AUTOSAR XML (schema 4-0-3)
package /ComponentTypes
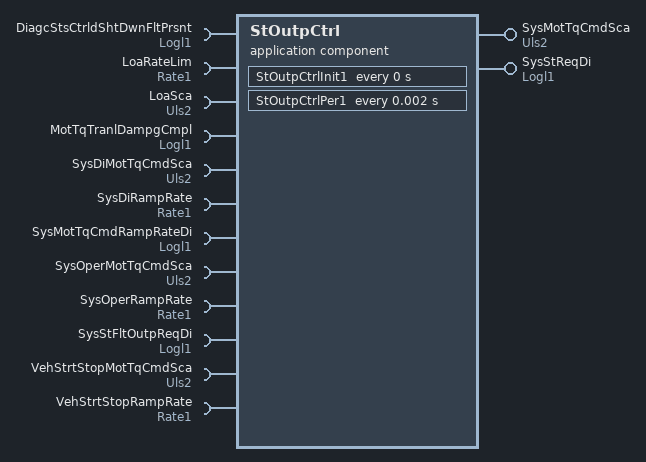
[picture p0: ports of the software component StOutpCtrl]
  application sw component type StOutpCtrl
    provide port SysMotTqCmdSca: nonqueued-sender-com-spec{data-element=Val, init-value=1}, provided-interface=Uls2
    provide port SysStReqDi: nonqueued-sender-com-spec{data-element=Logl, init-value=0}, provided-interface=Logl1
    12 x require port:
      DiagcStsCtrldShtDwnFltPrsnt: nonqueued-receiver-com-spec{data-element=Logl, filter=data-filter-type=ALWAYS, init-value=0}, required-interface=Logl1
      LoaRateLim: nonqueued-receiver-com-spec{data-element=Val, filter=data-filter-type=ALWAYS, init-value=1}, required-interface=Rate1
      LoaSca: nonqueued-receiver-com-spec{data-element=Val, filter=data-filter-type=ALWAYS, init-value=1}, required-interface=Uls2
      MotTqTranlDampgCmpl: nonqueued-receiver-com-spec{data-element=Logl, filter=data-filter-type=ALWAYS, init-value=0}, required-interface=Logl1
      SysDiMotTqCmdSca: nonqueued-receiver-com-spec{data-element=Val, filter=data-filter-type=ALWAYS, init-value=1}, required-interface=Uls2
      SysDiRampRate: nonqueued-receiver-com-spec{data-element=Val, filter=data-filter-type=ALWAYS, init-value=1}, required-interface=Rate1
      SysMotTqCmdRampRateDi: nonqueued-receiver-com-spec{data-element=Logl, filter=data-filter-type=ALWAYS, init-value=0}, required-interface=Logl1
      SysOperMotTqCmdSca: nonqueued-receiver-com-spec{data-element=Val, filter=data-filter-type=ALWAYS, init-value=1}, required-interface=Uls2
      SysOperRampRate: nonqueued-receiver-com-spec{data-element=Val, filter=data-filter-type=ALWAYS, init-value=1}, required-interface=Rate1
      SysStFltOutpReqDi: nonqueued-receiver-com-spec{data-element=Logl, filter=data-filter-type=ALWAYS, init-value=0}, required-interface=Logl1
      VehStrtStopMotTqCmdSca: nonqueued-receiver-com-spec{data-element=Val, filter=data-filter-type=ALWAYS, init-value=1}, required-interface=Uls2
      VehStrtStopRampRate: nonqueued-receiver-com-spec{data-element=Val, filter=data-filter-type=ALWAYS, init-value=1}, required-interface=Rate1
    behavior StOutpCtrl_InternalBehavior: data-type-mapping=Nexteer
      ar-typed-per-instance-memorys:
        4 x data, all with sw-calibration-access=READ-ONLY:
          dStOutpCtrlRateLim: type=Rate2
          dStOutpCtrlTarSca: type=Uls2
          StOutpCtrlPrevCmdSca: type=Uls2
          StOutpCtrlPrevSrc: type=Cnt21
      timing event StOutpCtrl_InitEvent: start-on-event=StOutpCtrlInit1, period=0
      timing event TMT_StOutpCtrlPer1: start-on-event=StOutpCtrlPer1, period=0.002
      runnable StOutpCtrlInit1
      runnable StOutpCtrlPer1
        data-receive-point-by-arguments:
          12 x access:
            REC_DiagcStsCtrldShtDwnFltPrsnt_Logl: accessed-variable=DiagcStsCtrldShtDwnFltPrsnt.Logl
            REC_LoaMotTqCmdSca_Val: accessed-variable=LoaSca.Val
            REC_LoaRampRate_Val: accessed-variable=LoaRateLim.Val
            REC_MotTqTranlDampgCmpl_Logl: accessed-variable=MotTqTranlDampgCmpl.Logl
            REC_SysDiMotTqCmdSca_Val: accessed-variable=SysDiMotTqCmdSca.Val
            REC_SysDiRampRate_Val: accessed-variable=SysDiRampRate.Val
            REC_SysDiRampToZeroActv_Logl: accessed-variable=SysStFltOutpReqDi.Logl
            REC_SysMotTqCmdRampRateDi_Logl: accessed-variable=SysMotTqCmdRampRateDi.Logl
            REC_SysOperMotTqCmdSca_Val: accessed-variable=SysOperMotTqCmdSca.Val
            REC_SysOperRampRate_Val: accessed-variable=SysOperRampRate.Val
            REC_VehStrtStopMotTqCmdSca_Val: accessed-variable=VehStrtStopMotTqCmdSca.Val
            REC_VehStrtStopRampRate_Val: accessed-variable=VehStrtStopRampRate.Val
        data-send-points:
          access SEND_SysMotTqCmdSca_Val: accessed-variable=SysMotTqCmdSca.Val
          access SEND_SysStReqDi_Logl: accessed-variable=SysStReqDi.Logl
  swc implementation StOutpCtrl_Implementation: behavior=StOutpCtrl_InternalBehavior
    code-descriptors:
      code Default: artifact-descriptors=autosar-engineering-object={short-label=Default, category=SWSRC}
